AUTOSAR XML (schema 314)
package /ComponentType
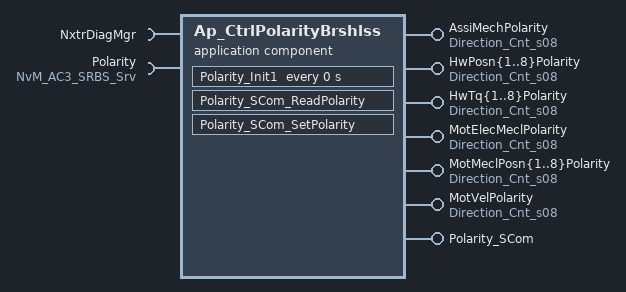
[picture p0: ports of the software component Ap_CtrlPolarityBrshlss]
  application software component type Ap_CtrlPolarityBrshlss
    28 x provide port:
      AssiMechPolarity: unqueued-sender-com-spec{data-element=Cnt_s08, can-invalidate=false, init-value=D_ZERO_CNT_S8}, provided-interface=Direction_Cnt_s08
      HwPosn{1..8}Polarity: unqueued-sender-com-spec{data-element=Cnt_s08, can-invalidate=false, init-value=D_ZERO_CNT_S8}, provided-interface=Direction_Cnt_s08
      HwTq{1..8}Polarity: unqueued-sender-com-spec{data-element=Cnt_s08, can-invalidate=false, init-value=D_ZERO_CNT_S8}, provided-interface=Direction_Cnt_s08
      MotElecMeclPolarity: unqueued-sender-com-spec{data-element=Cnt_s08, can-invalidate=false, init-value=D_ZERO_CNT_S8}, provided-interface=Direction_Cnt_s08
      MotMeclPosn{1..8}Polarity: unqueued-sender-com-spec{data-element=Cnt_s08, can-invalidate=false, init-value=D_ZERO_CNT_S8}, provided-interface=Direction_Cnt_s08
      MotVelPolarity: unqueued-sender-com-spec{data-element=Cnt_s08, can-invalidate=false, init-value=D_ZERO_CNT_S8}, provided-interface=Direction_Cnt_s08
      Polarity_SCom: provided-com-specs=[{operation=ReadPolarity, queue-length=1}, {operation=SetPolarity, queue-length=1}], provided-interface=Polarity_SCom
    require port NxtrDiagMgr: required-com-specs=[GetNTCActive, GetNTCFailed, GetNTCStatus, SetNTCStatus], required-interface=NxtrDiagMgr
    require port Polarity: required-com-specs=[EraseBlock, GetErrorStatus, InvalidateNvBlock, ReadBlock, SetRamBlockStatus, WriteBlock], required-interface=NvM_AC3_SRBS_Srv
  internal behavior Ap_CtrlPolarityBrshlss_InternalBehavior: component=Ap_CtrlPolarityBrshlss
    timing event Polarity_Init1_InitEvent: start-on-event=Polarity_Init1, period=0
    operation invoked event OIT_Polarity_SCom_ReadPolarity_Polarity_SCom_ReadPolarity: start-on-event=Polarity_SCom_ReadPolarity, operation=Polarity_SCom.ReadPolarity
    operation invoked event OIT_Polarity_SCom_SetPolarity_Polarity_SCom_SetPolarity: start-on-event=Polarity_SCom_SetPolarity, operation=Polarity_SCom.SetPolarity
    per instance memory Polarity_Cnt_Str: type=Polarity_DataType, type-definition=/DataType/Polarity_DataType
    port-api-options:
      enable-take-address=false, indirect-api=false, port=AssiMechPolarity
      enable-take-address=false, indirect-api=false, port=HwPosn{1..8}Polarity
      enable-take-address=false, indirect-api=false, port=HwTq{1..8}Polarity
      enable-take-address=false, indirect-api=false, port=MotElecMeclPolarity
      enable-take-address=false, indirect-api=false, port=MotMeclPosn{1..8}Polarity
      enable-take-address=false, indirect-api=false, port=MotVelPolarity
      enable-take-address=false, indirect-api=false, port=NxtrDiagMgr
      enable-take-address=false, indirect-api=false, port=Polarity
      enable-take-address=false, indirect-api=false, port=Polarity_SCom
    runnable Polarity_Init1
      27 x data send point:
        SEND_AssiMechPolarity_Cnt_s08: data-element=AssiMechPolarity.Cnt_s08
        SEND_HwPosn{1..8}Polarity_Cnt_s08: data-element=HwPosn{1..8}Polarity.Cnt_s08
        SEND_HwTq{1..8}Polarity_Cnt_s08: data-element=HwTq{1..8}Polarity.Cnt_s08
        SEND_MotElecMeclPolarity_Cnt_s08: data-element=MotElecMeclPolarity.Cnt_s08
        SEND_MotMeclPosn{1..8}Polarity_Cnt_s08: data-element=MotMeclPosn{1..8}Polarity.Cnt_s08
        SEND_MotVelPolarity_Cnt_s08: data-element=MotVelPolarity.Cnt_s08
      sync call SC_NxtrDiagMgr_SetNTCStatus: operation=NxtrDiagMgr.SetNTCStatus, timeout=0
    runnable Polarity_SCom_ReadPolarity
    runnable Polarity_SCom_SetPolarity
      sync call SC_Polarity_WriteBlock: operation=Polarity.WriteBlock, timeout=0
    service-needss:
      swc nv block needs PolarityBlock: n-data-sets=0, readonly=false, reliability=LOW, resistant-to-changed-sw=false, restore-at-start=false, write-only-once=false, writing-frequency=0, writing-priority=LOW, mirror-block=Polarity_Cnt_Str
  swc implementation Ap_CtrlPolarityBrshlss_Implementation: behavior=Ap_CtrlPolarityBrshlss_InternalBehavior
    code-descriptors:
      code Code: type=SRC
